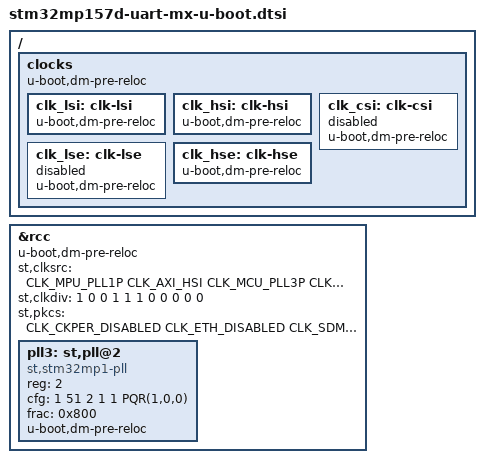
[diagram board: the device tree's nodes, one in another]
/* SPDX-License-Identifier: GPL-2.0+ OR BSD-3-Clause*/
/*
 * Copyright (C) 2020, STMicroelectronics - All Rights Reserved
 * Author: STM32CubeMX code generation for STMicroelectronics.
 */

/* For more information on Device Tree configuration, please refer to
 * https://wiki.st.com/stm32mpu/wiki/Category:Device_tree_configuration
 */

#include <dt-bindings/clock/stm32mp1-clksrc.h>

#include "stm32mp15-u-boot.dtsi"
/* !!! log : Warning - DDR not configured: unknown DDR dtsi  !!! */
/*#include "???-ddr.dtsi"*/

/* USER CODE BEGIN includes */
/* USER CODE END includes */

/ {

	/* USER CODE BEGIN root */
	/* USER CODE END root */

	clocks {
		u-boot,dm-pre-reloc;

		/* USER CODE BEGIN clocks */
		/* USER CODE END clocks */

#ifndef CONFIG_STM32MP1_TRUSTED
		clk_lsi: clk-lsi {
			u-boot,dm-pre-reloc;

			/* USER CODE BEGIN clk_lsi */
			/* USER CODE END clk_lsi */
		};
		clk_hsi: clk-hsi {
			u-boot,dm-pre-reloc;

			/* USER CODE BEGIN clk_hsi */
			/* USER CODE END clk_hsi */
		};
		clk_csi: clk-csi {
			u-boot,dm-pre-reloc;
			status = "disabled";

			/* USER CODE BEGIN clk_csi */
			/* USER CODE END clk_csi */
		};
		clk_lse: clk-lse {
			u-boot,dm-pre-reloc;
			status = "disabled";

			/* USER CODE BEGIN clk_lse */
			/* USER CODE END clk_lse */
		};
		clk_hse: clk-hse {
			u-boot,dm-pre-reloc;

			/* USER CODE BEGIN clk_hse */
			/* USER CODE END clk_hse */
		};
#endif	/*CONFIG_STM32MP1_TRUSTED*/
	};

}; /*root*/

#ifndef CONFIG_STM32MP1_TRUSTED

&rcc {
	u-boot,dm-pre-reloc;
	st,clksrc = <
		CLK_MPU_PLL1P
		CLK_AXI_HSI
		CLK_MCU_PLL3P
		CLK_PLL12_HSI
		CLK_PLL3_HSE
		CLK_PLL4_HSI
		CLK_RTC_LSI
		CLK_MCO1_DISABLED
		CLK_MCO2_DISABLED
	>;
	st,clkdiv = <
		1 		/*MPU*/
		0 		/*AXI*/
		0 		/*MCU*/
		1 		/*APB1*/
		1 		/*APB2*/
		1 		/*APB3*/
		0 		/*APB4*/
		0 		/*APB5*/
		0 		/*RTC*/
		0 		/*MCO1*/
		0 		/*MCO2*/
	>;
	st,pkcs = <
		CLK_CKPER_DISABLED
		CLK_ETH_DISABLED
		CLK_SDMMC12_DISABLED
		CLK_STGEN_HSI
		CLK_USBPHY_DISABLED
		CLK_SPI2S1_DISABLED
		CLK_SPI2S23_DISABLED
		CLK_SPI45_DISABLED
		CLK_SPI6_DISABLED
		CLK_I2C46_DISABLED
		CLK_SDMMC3_DISABLED
		CLK_ADC_DISABLED
		CLK_CEC_DISABLED
		CLK_I2C12_DISABLED
		CLK_I2C35_DISABLED
		CLK_UART1_DISABLED
		CLK_UART24_PCLK1
		CLK_UART35_DISABLED
		CLK_UART6_DISABLED
		CLK_UART78_DISABLED
		CLK_SPDIF_DISABLED
		CLK_SAI1_DISABLED
		CLK_SAI2_DISABLED
		CLK_SAI3_DISABLED
		CLK_SAI4_DISABLED
		CLK_LPTIM1_DISABLED
		CLK_LPTIM23_DISABLED
		CLK_LPTIM45_DISABLED
	>;
	pll3:st,pll@2 {
		compatible = "st,stm32mp1-pll";
		reg = <2>;
		cfg = < 1 51 2 1 1 PQR(1,0,0) >;
		frac = < 0x800 >;
		u-boot,dm-pre-reloc;
	};
};

#endif	/*CONFIG_STM32MP1_TRUSTED*/

/* USER CODE BEGIN addons */
/* USER CODE END addons */

